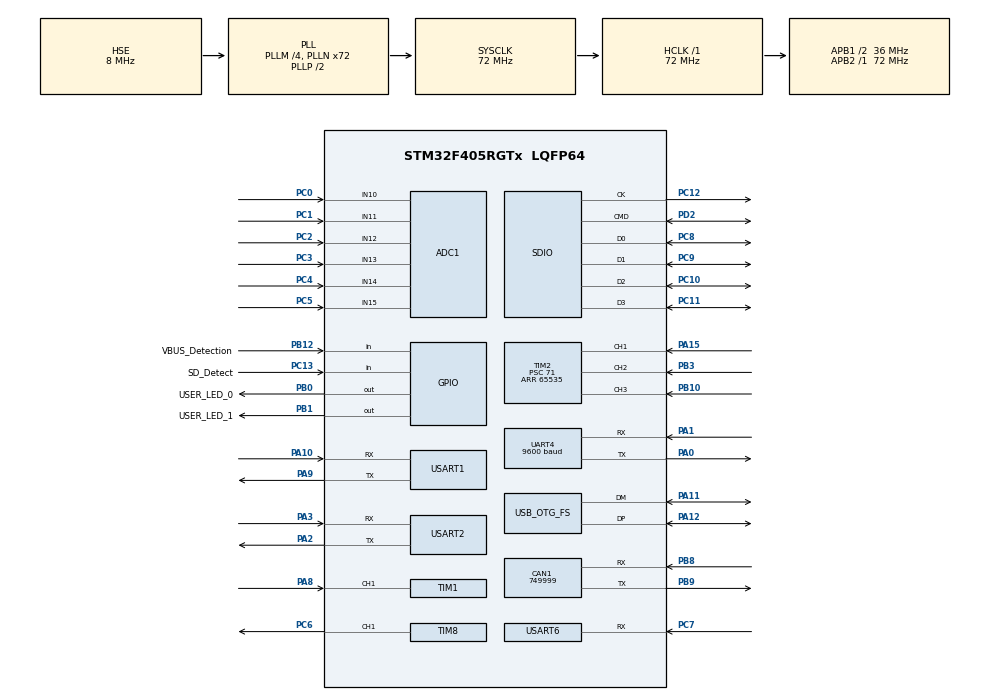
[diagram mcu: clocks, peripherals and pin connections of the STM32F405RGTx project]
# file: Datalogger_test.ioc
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ADC1.Channel-0\#ChannelRegularConversion=ADC_CHANNEL_10
ADC1.ExternalTrigConv=ADC_EXTERNALTRIGCONV_T3_TRGO
ADC1.NbrOfConversionFlag=1
ADC1.Rank-0\#ChannelRegularConversion=1
ADC1.SamplingTime-0\#ChannelRegularConversion=ADC_SAMPLETIME_3CYCLES
ADC1.ScanConvMode=ENABLE
ADC1.master=1
CAN1.CalculateBaudRate=749999
CAN1.CalculateTimeBit=1333
CAN1.CalculateTimeQuantum=444.44444444444446
Dma.ADC1.0.Direction=DMA_PERIPH_TO_MEMORY
Dma.ADC1.0.FIFOMode=DMA_FIFOMODE_DISABLE
Dma.ADC1.0.Instance=DMA2_Stream0
Dma.ADC1.0.MemDataAlignment=DMA_MDATAALIGN_HALFWORD
Dma.ADC1.0.MemInc=DMA_MINC_ENABLE
Dma.ADC1.0.Mode=DMA_CIRCULAR
Dma.ADC1.0.PeriphDataAlignment=DMA_PDATAALIGN_HALFWORD
Dma.ADC1.0.PeriphInc=DMA_PINC_DISABLE
Dma.ADC1.0.Priority=DMA_PRIORITY_HIGH
Dma.Request0=ADC1
Dma.Request1=TIM8_CH1
Dma.Request2=USART6_RX
Dma.TIM8_CH1.1.Direction=DMA_MEMORY_TO_PERIPH
Dma.TIM8_CH1.1.FIFOMode=DMA_FIFOMODE_DISABLE
Dma.TIM8_CH1.1.Instance=DMA2_Stream2
Dma.TIM8_CH1.1.MemDataAlignment=DMA_MDATAALIGN_HALFWORD
Dma.TIM8_CH1.1.MemInc=DMA_MINC_ENABLE
Dma.TIM8_CH1.1.Mode=DMA_NORMAL
Dma.TIM8_CH1.1.PeriphDataAlignment=DMA_PDATAALIGN_HALFWORD
Dma.TIM8_CH1.1.PeriphInc=DMA_PINC_DISABLE
Dma.TIM8_CH1.1.Priority=DMA_PRIORITY_LOW
Dma.USART6_RX.2.Direction=DMA_PERIPH_TO_MEMORY
Dma.USART6_RX.2.FIFOMode=DMA_FIFOMODE_DISABLE
Dma.USART6_RX.2.Instance=DMA2_Stream1
Dma.USART6_RX.2.MemDataAlignment=DMA_MDATAALIGN_BYTE
Dma.USART6_RX.2.MemInc=DMA_MINC_ENABLE
Dma.USART6_RX.2.Mode=DMA_CIRCULAR
Dma.USART6_RX.2.PeriphDataAlignment=DMA_PDATAALIGN_BYTE
Dma.USART6_RX.2.PeriphInc=DMA_PINC_DISABLE
Dma.USART6_RX.2.Priority=DMA_PRIORITY_HIGH
FATFS.BSP.number=1
FATFS._USE_LFN=1
FATFS0.BSP.STBoard=false
FATFS0.BSP.api=Unknown
FATFS0.BSP.instance=PC13-ANTI_TAMP
FATFS0.BSP.ip=GPIO
FATFS0.BSP.mode=Input
FATFS0.BSP.name=Detect_SDIO
FATFS0.BSP.solution=PC13-ANTI_TAMP
Mcu.Family=STM32F4
Mcu.Name=STM32F405RGTx
Mcu.Package=LQFP64
NVIC.DMA2_Stream0_IRQn=true\:0\:0\:false\:false\:true\:false\:true\:true
NVIC.DMA2_Stream1_IRQn=true\:5\:0\:false\:false\:true\:false\:true\:true
NVIC.DMA2_Stream2_IRQn=true\:0\:0\:false\:false\:true\:false\:true\:true
NVIC.OTG_FS_IRQn=true\:0\:0\:false\:false\:true\:false\:true\:true
NVIC.PriorityGroup=NVIC_PRIORITYGROUP_4
NVIC.TIM1_CC_IRQn=true\:0\:0\:false\:false\:true\:true\:true\:true
NVIC.USART1_IRQn=true\:0\:0\:false\:false\:true\:true\:true\:true
NVIC.USART2_IRQn=true\:0\:0\:false\:false\:true\:true\:true\:true
NVIC.USART6_IRQn=true\:5\:0\:false\:false\:true\:true\:true\:true
PA0-WKUP.Mode=Asynchronous
PA0-WKUP.Signal=UART4_TX
PA1.Mode=Asynchronous
PA1.Signal=UART4_RX
PA10.Mode=Asynchronous
PA10.Signal=USART1_RX
PA11.Mode=Device_Only
PA11.Signal=USB_OTG_FS_DM
PA12.Mode=Device_Only
PA12.Signal=USB_OTG_FS_DP
PA13.Mode=Serial_Wire
PA13.Signal=SYS_JTMS-SWDIO
PA14.Mode=Serial_Wire
PA14.Signal=SYS_JTCK-SWCLK
PA15.Signal=S_TIM2_CH1_ETR
PA2.Mode=Asynchronous
PA2.Signal=USART2_TX
PA3.Mode=Asynchronous
PA3.Signal=USART2_RX
PA8.Signal=S_TIM1_CH1
PA9.Mode=Asynchronous
PA9.Signal=USART1_TX
PC7.Mode=Asynchronous
PC7.Signal=USART6_RX
PB0.GPIO_Label=USER_LED_0
PB0.Signal=GPIO_Output
PB1.GPIO_Label=USER_LED_1
PB1.Signal=GPIO_Output
PB10.Signal=S_TIM2_CH3
PB12.GPIO_Label=VBUS_Detection
PB12.Signal=GPIO_Input
PB3.Signal=S_TIM2_CH2
PB8.Mode=CAN_Activate
PB8.Signal=CAN1_RX
PB9.Mode=CAN_Activate
PB9.Signal=CAN1_TX
PC0.Signal=ADCx_IN10
PC1.Signal=ADCx_IN11
PC10.Mode=SD_4_bits_Wide_bus
PC10.Signal=SDIO_D2
PC11.Mode=SD_4_bits_Wide_bus
PC11.Signal=SDIO_D3
PC12.Mode=SD_4_bits_Wide_bus
PC12.Signal=SDIO_CK
PC13-ANTI_TAMP.GPIO_Label=SD_Detect
PC13-ANTI_TAMP.Signal=GPIO_Input
PC2.Signal=ADCx_IN12
PC3.Signal=ADCx_IN13
PC4.Signal=ADCx_IN14
PC5.Signal=ADCx_IN15
PC6.Signal=S_TIM8_CH1
PC8.Mode=SD_4_bits_Wide_bus
PC8.Signal=SDIO_D0
PC9.Mode=SD_4_bits_Wide_bus
PC9.Signal=SDIO_D1
PD2.Mode=SD_4_bits_Wide_bus
PD2.Signal=SDIO_CMD
PH0-OSC_IN.Mode=HSE-External-Oscillator
PH0-OSC_IN.Signal=RCC_OSC_IN
PH1-OSC_OUT.Mode=HSE-External-Oscillator
PH1-OSC_OUT.Signal=RCC_OSC_OUT
ProjectManager.HeapSize=0x400
ProjectManager.StackSize=0x800
ProjectManager.TargetToolchain=STM32CubeIDE
RCC.48MHZClocksFreq_Value=48000000
RCC.AHBFreq_Value=72000000
RCC.APB1CLKDivider=RCC_HCLK_DIV2
RCC.APB1Freq_Value=36000000
RCC.APB1TimFreq_Value=72000000
RCC.APB2Freq_Value=72000000
RCC.APB2TimFreq_Value=72000000
RCC.CortexFreq_Value=72000000
RCC.HCLKFreq_Value=72000000
RCC.HSE_VALUE=8000000
RCC.HSI_VALUE=16000000
RCC.LSE_VALUE=32768
RCC.PLLM=4
RCC.PLLN=72
RCC.PLLQ=3
RCC.SYSCLKFreq_VALUE=72000000
RCC.SYSCLKSource=RCC_SYSCLKSOURCE_PLLCLK
RCC.VCOOutputFreq_Value=144000000
SDIO.ClockDiv=4
SH.ADCx_IN10.0=ADC1_IN10,IN10
SH.ADCx_IN11.0=ADC1_IN11,IN11
SH.ADCx_IN12.0=ADC1_IN12,IN12
SH.ADCx_IN13.0=ADC1_IN13,IN13
SH.ADCx_IN14.0=ADC1_IN14,IN14
SH.ADCx_IN15.0=ADC1_IN15,IN15
SH.S_TIM1_CH1.0=TIM1_CH1,Input_Capture1_from_TI1
SH.S_TIM2_CH1_ETR.0=TIM2_CH1,Input_Capture1_from_TI1
SH.S_TIM2_CH2.0=TIM2_CH2,Input_Capture2_from_TI2
SH.S_TIM2_CH3.0=TIM2_CH3,Input_Capture3_from_TI3
SH.S_TIM8_CH1.0=TIM8_CH1,PWM Generation1 CH1
TIM1.Channel-Input_Capture1_from_TI1=TIM_CHANNEL_1
TIM1.ICPolarity_CH1=TIM_INPUTCHANNELPOLARITY_FALLING
TIM1.Prescaler=71
TIM2.Channel-Input_Capture1_from_TI1=TIM_CHANNEL_1
TIM2.Channel-Input_Capture2_from_TI2=TIM_CHANNEL_2
TIM2.Channel-Input_Capture3_from_TI3=TIM_CHANNEL_3
TIM2.ICPolarity_CH1=TIM_INPUTCHANNELPOLARITY_FALLING
TIM2.ICPolarity_CH2=TIM_INPUTCHANNELPOLARITY_FALLING
TIM2.ICPolarity_CH3=TIM_INPUTCHANNELPOLARITY_FALLING
TIM2.Period=65535
TIM2.Prescaler=71
TIM3.MasterOutputTrigger=TIM_TRGO_UPDATE
TIM3.Period=9999
TIM3.Prescaler=71
TIM8.Channel-PWM\ Generation1\ CH1=TIM_CHANNEL_1
TIM8.Period=89
UART4.BaudRate=9600
UART4.VirtualMode=Asynchronous
USART1.VirtualMode=VM_ASYNC
USART2.VirtualMode=VM_ASYNC
USART6.BaudRate=115200
USART6.Mode=MODE_RX
USART6.VirtualMode=VM_ASYNC
USB_DEVICE.CLASS_NAME_FS=MSC
USB_DEVICE.VirtualMode-MSC_FS=Msc
USB_DEVICE.VirtualModeFS=Msc_FS
USB_OTG_FS.VirtualMode=Device_Only
VP_FATFS_VS_SDIO.Mode=SDIO
VP_TIM2_VS_ClockSourceINT.Mode=Internal
VP_USB_DEVICE_VS_USB_DEVICE_MSC_FS.Mode=MSC_FS
board=custom

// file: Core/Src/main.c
/* USER CODE BEGIN Header */
/**
 ******************************************************************************
 * @file           : main.c
 * @brief          : Main program body
 ******************************************************************************
 * @attention
 *
 * Copyright (c) 2026 STMicroelectronics.
 * All rights reserved.
 *
 * This software is licensed under terms that can be found in the LICENSE file
 * in the root directory of this software component.
 * If no LICENSE file comes with this software, it is provided AS-IS.
 *
 ******************************************************************************
 */
/* USER CODE END Header */
#include "main.h"
#include "fatfs.h"
#include "usb_device.h"

/* USER CODE BEGIN Includes */
#include "app_internal.h"
/* USER CODE END Includes */

ADC_HandleTypeDef hadc1;
DMA_HandleTypeDef hdma_adc1;

CAN_HandleTypeDef hcan1;

SD_HandleTypeDef hsd;

TIM_HandleTypeDef htim1;
TIM_HandleTypeDef htim2;
TIM_HandleTypeDef htim3;
TIM_HandleTypeDef htim8;
DMA_HandleTypeDef hdma_tim8_ch1;

UART_HandleTypeDef huart4;
UART_HandleTypeDef huart1;
UART_HandleTypeDef huart2;
UART_HandleTypeDef huart6;
DMA_HandleTypeDef hdma_usart6_rx;

void SystemClock_Config(void);
static void MX_GPIO_Init(void);
static void MX_DMA_Init(void);
static void MX_SDIO_SD_Init(void);
static void MX_CAN1_Init(void);
static void MX_TIM1_Init(void);
static void MX_ADC1_Init(void);
static void MX_TIM2_Init(void);
static void MX_TIM3_Init(void);
static void MX_UART4_Init(void);
static void MX_USART1_UART_Init(void);
static void MX_USART2_UART_Init(void);
static void MX_USART6_UART_Init(void);
static void MX_TIM8_Init(void);

int main(void) {

  /* MCU Configuration--------------------------------------------------------*/

  /* Reset of all peripherals, Initializes the Flash interface and the Systick.
   */
  HAL_Init();

  /* Configure the system clock */
  SystemClock_Config();

  /* Initialize all configured peripherals */
  MX_GPIO_Init();
  MX_DMA_Init();
  MX_SDIO_SD_Init();
  MX_FATFS_Init();
  MX_CAN1_Init();
  MX_TIM1_Init();
  MX_TIM2_Init();
  MX_TIM3_Init();
  MX_ADC1_Init();
  MX_UART4_Init();
  MX_USART1_UART_Init();
  MX_USART2_UART_Init();
  MX_USART6_UART_Init();
  MX_TIM8_Init();

  /* USER CODE BEGIN 2 */
App_Init();
/* USER CODE END 2 */

  /* Infinite loop */
  while (1) {

    /* USER CODE BEGIN 3 */
    App_Process();
  }
  /* USER CODE END 3 */
}

void SystemClock_Config(void) {
  RCC_OscInitTypeDef RCC_OscInitStruct = {0};
  RCC_ClkInitTypeDef RCC_ClkInitStruct = {0};

  /** Configure the main internal regulator output voltage
   */
  __HAL_RCC_PWR_CLK_ENABLE();
  __HAL_PWR_VOLTAGESCALING_CONFIG(PWR_REGULATOR_VOLTAGE_SCALE1);

  /** Initializes the RCC Oscillators according to the specified parameters
   * in the RCC_OscInitTypeDef structure.
   */
  RCC_OscInitStruct.OscillatorType = RCC_OSCILLATORTYPE_HSE;
  RCC_OscInitStruct.HSEState = RCC_HSE_ON;
  RCC_OscInitStruct.PLL.PLLState = RCC_PLL_ON;
  RCC_OscInitStruct.PLL.PLLSource = RCC_PLLSOURCE_HSE;
  RCC_OscInitStruct.PLL.PLLM = 4;
  RCC_OscInitStruct.PLL.PLLN = 72;
  RCC_OscInitStruct.PLL.PLLP = RCC_PLLP_DIV2;
  RCC_OscInitStruct.PLL.PLLQ = 3;
  if (HAL_RCC_OscConfig(&RCC_OscInitStruct) != HAL_OK) {
    Error_Handler();
  }

  /** Initializes the CPU, AHB and APB buses clocks
   */
  RCC_ClkInitStruct.ClockType = RCC_CLOCKTYPE_HCLK | RCC_CLOCKTYPE_SYSCLK |
                                RCC_CLOCKTYPE_PCLK1 | RCC_CLOCKTYPE_PCLK2;
  RCC_ClkInitStruct.SYSCLKSource = RCC_SYSCLKSOURCE_PLLCLK;
  RCC_ClkInitStruct.AHBCLKDivider = RCC_SYSCLK_DIV1;
  RCC_ClkInitStruct.APB1CLKDivider = RCC_HCLK_DIV2;
  RCC_ClkInitStruct.APB2CLKDivider = RCC_HCLK_DIV1;

  if (HAL_RCC_ClockConfig(&RCC_ClkInitStruct, FLASH_LATENCY_2) != HAL_OK) {
    Error_Handler();
  }
}

static void MX_ADC1_Init(void) {
  static const uint32_t adc_channels[ADC_DMA_CHANNEL_COUNT] = {
      ADC_CHANNEL_10, ADC_CHANNEL_13, ADC_CHANNEL_14, ADC_CHANNEL_15};
  ADC_ChannelConfTypeDef sConfig = {0};

  hadc1.Instance = ADC1;
  hadc1.Init.ClockPrescaler = ADC_CLOCK_SYNC_PCLK_DIV2;
  hadc1.Init.Resolution = ADC_RESOLUTION_12B;
  hadc1.Init.ScanConvMode = ENABLE;
  hadc1.Init.ContinuousConvMode = DISABLE;
  hadc1.Init.DiscontinuousConvMode = DISABLE;
  hadc1.Init.ExternalTrigConvEdge = ADC_EXTERNALTRIGCONVEDGE_RISING;
  hadc1.Init.ExternalTrigConv = ADC_EXTERNALTRIGCONV_T3_TRGO;
  hadc1.Init.DataAlign = ADC_DATAALIGN_RIGHT;
  hadc1.Init.NbrOfConversion = ADC_DMA_CHANNEL_COUNT;
  hadc1.Init.DMAContinuousRequests = ENABLE;
  hadc1.Init.EOCSelection = ADC_EOC_SEQ_CONV;
  if (HAL_ADC_Init(&hadc1) != HAL_OK) {
    Error_Handler();
  }

  sConfig.SamplingTime = ADC_SAMPLETIME_480CYCLES;
  for (uint32_t i = 0U; i < ADC_DMA_CHANNEL_COUNT; i++) {
    sConfig.Channel = adc_channels[i];
    sConfig.Rank = (uint32_t)(i + 1U);
    if (HAL_ADC_ConfigChannel(&hadc1, &sConfig) != HAL_OK) {
      Error_Handler();
    }
  }
}

static void MX_CAN1_Init(void) {

  hcan1.Instance = CAN1;
  hcan1.Init.Prescaler = 16;
  hcan1.Init.Mode = CAN_MODE_NORMAL;
  hcan1.Init.SyncJumpWidth = CAN_SJW_1TQ;
  hcan1.Init.TimeSeg1 = CAN_BS1_1TQ;
  hcan1.Init.TimeSeg2 = CAN_BS2_1TQ;
  hcan1.Init.TimeTriggeredMode = DISABLE;
  hcan1.Init.AutoBusOff = DISABLE;
  hcan1.Init.AutoWakeUp = DISABLE;
  hcan1.Init.AutoRetransmission = DISABLE;
  hcan1.Init.ReceiveFifoLocked = DISABLE;
  hcan1.Init.TransmitFifoPriority = DISABLE;
  if (HAL_CAN_Init(&hcan1) != HAL_OK) {
    Error_Handler();
  }
}

static void MX_SDIO_SD_Init(void) {

  hsd.Instance = SDIO;
  hsd.Init.ClockEdge = SDIO_CLOCK_EDGE_RISING;
  hsd.Init.ClockBypass = SDIO_CLOCK_BYPASS_DISABLE;
  hsd.Init.ClockPowerSave = SDIO_CLOCK_POWER_SAVE_DISABLE;
  hsd.Init.BusWide = SDIO_BUS_WIDE_1B;
  hsd.Init.HardwareFlowControl = SDIO_HARDWARE_FLOW_CONTROL_DISABLE;
  hsd.Init.ClockDiv = 4;
  /* USER CODE BEGIN SDIO_Init 2 */
  /* The logger writes slowly, so prefer signal margin over bus speed. Hardware
   * flow control also lets SDIO pause the clock while the FIFO is tight, which
   * is useful with long wires or marginal cards.
   */
  hsd.Init.HardwareFlowControl = SDIO_HARDWARE_FLOW_CONTROL_ENABLE;
  hsd.Init.ClockDiv = 12;

  /* USER CODE END SDIO_Init 2 */
}

static void MX_TIM1_Init(void) {

  TIM_MasterConfigTypeDef sMasterConfig = {0};
  TIM_IC_InitTypeDef sConfigIC = {0};

  htim1.Instance = TIM1;
  htim1.Init.Prescaler = 71;
  htim1.Init.CounterMode = TIM_COUNTERMODE_UP;
  htim1.Init.Period = 65535;
  htim1.Init.ClockDivision = TIM_CLOCKDIVISION_DIV1;
  htim1.Init.RepetitionCounter = 0;
  htim1.Init.AutoReloadPreload = TIM_AUTORELOAD_PRELOAD_DISABLE;
  if (HAL_TIM_IC_Init(&htim1) != HAL_OK) {
    Error_Handler();
  }
  sMasterConfig.MasterOutputTrigger = TIM_TRGO_RESET;
  sMasterConfig.MasterSlaveMode = TIM_MASTERSLAVEMODE_DISABLE;
  if (HAL_TIMEx_MasterConfigSynchronization(&htim1, &sMasterConfig) != HAL_OK) {
    Error_Handler();
  }
  sConfigIC.ICPolarity = TIM_INPUTCHANNELPOLARITY_FALLING;
  sConfigIC.ICSelection = TIM_ICSELECTION_DIRECTTI;
  sConfigIC.ICPrescaler = TIM_ICPSC_DIV1;
  sConfigIC.ICFilter = 0;
  if (HAL_TIM_IC_ConfigChannel(&htim1, &sConfigIC, TIM_CHANNEL_1) != HAL_OK) {
    Error_Handler();
  }
}

static void MX_TIM2_Init(void) {

  TIM_ClockConfigTypeDef sClockSourceConfig = {0};
  TIM_MasterConfigTypeDef sMasterConfig = {0};
  TIM_IC_InitTypeDef sConfigIC = {0};

  htim2.Instance = TIM2;
  htim2.Init.Prescaler = 71;
  htim2.Init.CounterMode = TIM_COUNTERMODE_UP;
  htim2.Init.Period = 65535;
  htim2.Init.ClockDivision = TIM_CLOCKDIVISION_DIV1;
  htim2.Init.AutoReloadPreload = TIM_AUTORELOAD_PRELOAD_DISABLE;
  if (HAL_TIM_Base_Init(&htim2) != HAL_OK) {
    Error_Handler();
  }
  sClockSourceConfig.ClockSource = TIM_CLOCKSOURCE_INTERNAL;
  if (HAL_TIM_ConfigClockSource(&htim2, &sClockSourceConfig) != HAL_OK) {
    Error_Handler();
  }
  if (HAL_TIM_IC_Init(&htim2) != HAL_OK) {
    Error_Handler();
  }
  sMasterConfig.MasterOutputTrigger = TIM_TRGO_RESET;
  sMasterConfig.MasterSlaveMode = TIM_MASTERSLAVEMODE_DISABLE;
  if (HAL_TIMEx_MasterConfigSynchronization(&htim2, &sMasterConfig) != HAL_OK) {
    Error_Handler();
  }
  sConfigIC.ICPolarity = TIM_INPUTCHANNELPOLARITY_FALLING;
  sConfigIC.ICSelection = TIM_ICSELECTION_DIRECTTI;
  sConfigIC.ICPrescaler = TIM_ICPSC_DIV1;
  sConfigIC.ICFilter = 0;
  if (HAL_TIM_IC_ConfigChannel(&htim2, &sConfigIC, TIM_CHANNEL_1) != HAL_OK) {
    Error_Handler();
  }
  if (HAL_TIM_IC_ConfigChannel(&htim2, &sConfigIC, TIM_CHANNEL_2) != HAL_OK) {
    Error_Handler();
  }
  if (HAL_TIM_IC_ConfigChannel(&htim2, &sConfigIC, TIM_CHANNEL_3) != HAL_OK) {
    Error_Handler();
  }
}

static void MX_TIM3_Init(void) {
  TIM_ClockConfigTypeDef sClockSourceConfig = {0};
  TIM_MasterConfigTypeDef sMasterConfig = {0};

  /* 72 MHz APB1 timer clock / 72 = 1 MHz. An update every 10,000 ticks
   * provides a dedicated 100 Hz trigger for the four local ADC channels. */
  htim3.Instance = TIM3;
  htim3.Init.Prescaler = 71;
  htim3.Init.CounterMode = TIM_COUNTERMODE_UP;
  htim3.Init.Period = 9999;
  htim3.Init.ClockDivision = TIM_CLOCKDIVISION_DIV1;
  htim3.Init.AutoReloadPreload = TIM_AUTORELOAD_PRELOAD_DISABLE;
  if (HAL_TIM_Base_Init(&htim3) != HAL_OK) {
    Error_Handler();
  }

  sClockSourceConfig.ClockSource = TIM_CLOCKSOURCE_INTERNAL;
  if (HAL_TIM_ConfigClockSource(&htim3, &sClockSourceConfig) != HAL_OK) {
    Error_Handler();
  }

  sMasterConfig.MasterOutputTrigger = TIM_TRGO_UPDATE;
  sMasterConfig.MasterSlaveMode = TIM_MASTERSLAVEMODE_DISABLE;
  if (HAL_TIMEx_MasterConfigSynchronization(&htim3, &sMasterConfig) != HAL_OK) {
    Error_Handler();
  }
}

static void MX_TIM8_Init(void) {

  TIM_MasterConfigTypeDef sMasterConfig = {0};
  TIM_OC_InitTypeDef sConfigOC = {0};
  TIM_BreakDeadTimeConfigTypeDef sBreakDeadTimeConfig = {0};

  htim8.Instance = TIM8;
  htim8.Init.Prescaler = 0;
  htim8.Init.CounterMode = TIM_COUNTERMODE_UP;
  htim8.Init.Period = 89;
  htim8.Init.ClockDivision = TIM_CLOCKDIVISION_DIV1;
  htim8.Init.RepetitionCounter = 0;
  htim8.Init.AutoReloadPreload = TIM_AUTORELOAD_PRELOAD_DISABLE;
  if (HAL_TIM_PWM_Init(&htim8) != HAL_OK) {
    Error_Handler();
  }
  sMasterConfig.MasterOutputTrigger = TIM_TRGO_RESET;
  sMasterConfig.MasterSlaveMode = TIM_MASTERSLAVEMODE_DISABLE;
  if (HAL_TIMEx_MasterConfigSynchronization(&htim8, &sMasterConfig) != HAL_OK) {
    Error_Handler();
  }
  sConfigOC.OCMode = TIM_OCMODE_PWM1;
  sConfigOC.Pulse = 0;
  sConfigOC.OCPolarity = TIM_OCPOLARITY_HIGH;
  sConfigOC.OCNPolarity = TIM_OCNPOLARITY_HIGH;
  sConfigOC.OCFastMode = TIM_OCFAST_DISABLE;
  sConfigOC.OCIdleState = TIM_OCIDLESTATE_RESET;
  sConfigOC.OCNIdleState = TIM_OCNIDLESTATE_RESET;
  if (HAL_TIM_PWM_ConfigChannel(&htim8, &sConfigOC, TIM_CHANNEL_1) != HAL_OK) {
    Error_Handler();
  }
  sBreakDeadTimeConfig.OffStateRunMode = TIM_OSSR_DISABLE;
  sBreakDeadTimeConfig.OffStateIDLEMode = TIM_OSSI_DISABLE;
  sBreakDeadTimeConfig.LockLevel = TIM_LOCKLEVEL_OFF;
  sBreakDeadTimeConfig.DeadTime = 0;
  sBreakDeadTimeConfig.BreakState = TIM_BREAK_DISABLE;
  sBreakDeadTimeConfig.BreakPolarity = TIM_BREAKPOLARITY_HIGH;
  sBreakDeadTimeConfig.AutomaticOutput = TIM_AUTOMATICOUTPUT_DISABLE;
  if (HAL_TIMEx_ConfigBreakDeadTime(&htim8, &sBreakDeadTimeConfig) != HAL_OK) {
    Error_Handler();
  }
  HAL_TIM_MspPostInit(&htim8);
}

static void MX_UART4_Init(void) {

  huart4.Instance = UART4;
  huart4.Init.BaudRate = 9600;
  huart4.Init.WordLength = UART_WORDLENGTH_8B;
  huart4.Init.StopBits = UART_STOPBITS_1;
  huart4.Init.Parity = UART_PARITY_NONE;
  huart4.Init.Mode = UART_MODE_TX_RX;
  huart4.Init.HwFlowCtl = UART_HWCONTROL_NONE;
  huart4.Init.OverSampling = UART_OVERSAMPLING_16;
  if (HAL_UART_Init(&huart4) != HAL_OK) {
    Error_Handler();
  }
}

static void MX_USART1_UART_Init(void) {

  huart1.Instance = USART1;
  huart1.Init.BaudRate = 115200;
  huart1.Init.WordLength = UART_WORDLENGTH_8B;
  huart1.Init.StopBits = UART_STOPBITS_1;
  huart1.Init.Parity = UART_PARITY_NONE;
  huart1.Init.Mode = UART_MODE_TX_RX;
  huart1.Init.HwFlowCtl = UART_HWCONTROL_NONE;
  huart1.Init.OverSampling = UART_OVERSAMPLING_16;
  if (HAL_UART_Init(&huart1) != HAL_OK) {
    Error_Handler();
  }
}

static void MX_USART2_UART_Init(void) {

  huart2.Instance = USART2;
  huart2.Init.BaudRate = 115200;
  huart2.Init.WordLength = UART_WORDLENGTH_8B;
  huart2.Init.StopBits = UART_STOPBITS_1;
  huart2.Init.Parity = UART_PARITY_NONE;
  huart2.Init.Mode = UART_MODE_TX_RX;
  huart2.Init.HwFlowCtl = UART_HWCONTROL_NONE;
  huart2.Init.OverSampling = UART_OVERSAMPLING_16;
  if (HAL_UART_Init(&huart2) != HAL_OK) {
    Error_Handler();
  }
}

static void MX_USART6_UART_Init(void) {
  huart6.Instance = USART6;
  huart6.Init.BaudRate = 115200;
  huart6.Init.WordLength = UART_WORDLENGTH_8B;
  huart6.Init.StopBits = UART_STOPBITS_1;
  huart6.Init.Parity = UART_PARITY_NONE;
  huart6.Init.Mode = UART_MODE_RX;
  huart6.Init.HwFlowCtl = UART_HWCONTROL_NONE;
  huart6.Init.OverSampling = UART_OVERSAMPLING_16;
  if (HAL_UART_Init(&huart6) != HAL_OK) {
    Error_Handler();
  }
}

static void MX_DMA_Init(void) {

  /* DMA controller clock enable */
  __HAL_RCC_DMA2_CLK_ENABLE();

  /* DMA interrupt init */
  /* DMA2_Stream0_IRQn interrupt configuration */
  HAL_NVIC_SetPriority(DMA2_Stream0_IRQn, 0, 0);
  HAL_NVIC_EnableIRQ(DMA2_Stream0_IRQn);
  /* DMA2_Stream2_IRQn interrupt configuration */
  HAL_NVIC_SetPriority(DMA2_Stream2_IRQn, 0, 0);
  HAL_NVIC_EnableIRQ(DMA2_Stream2_IRQn);
  /* DMA2_Stream1_IRQn interrupt configuration (USART6 RX) */
  HAL_NVIC_SetPriority(DMA2_Stream1_IRQn, 5, 0);
  HAL_NVIC_EnableIRQ(DMA2_Stream1_IRQn);
}

static void MX_GPIO_Init(void) {
  GPIO_InitTypeDef GPIO_InitStruct = {0};

  /* GPIO Ports Clock Enable */
  __HAL_RCC_GPIOC_CLK_ENABLE();
  __HAL_RCC_GPIOH_CLK_ENABLE();
  __HAL_RCC_GPIOA_CLK_ENABLE();
  __HAL_RCC_GPIOB_CLK_ENABLE();
  __HAL_RCC_GPIOD_CLK_ENABLE();

  /*Configure GPIO pin Output Level */
  HAL_GPIO_WritePin(GPIOB, USER_LED_0_Pin | USER_LED_1_Pin, GPIO_PIN_RESET);

  /*Configure GPIO pin : SD_Detect_Pin */
  GPIO_InitStruct.Pin = SD_Detect_Pin;
  GPIO_InitStruct.Mode = GPIO_MODE_INPUT;
  GPIO_InitStruct.Pull = GPIO_NOPULL;
  HAL_GPIO_Init(SD_Detect_GPIO_Port, &GPIO_InitStruct);

  /*Configure GPIO pins : USER_LED_0_Pin USER_LED_1_Pin */
  GPIO_InitStruct.Pin = USER_LED_0_Pin | USER_LED_1_Pin;
  GPIO_InitStruct.Mode = GPIO_MODE_OUTPUT_PP;
  GPIO_InitStruct.Pull = GPIO_NOPULL;
  GPIO_InitStruct.Speed = GPIO_SPEED_FREQ_LOW;
  HAL_GPIO_Init(GPIOB, &GPIO_InitStruct);

  /*Configure GPIO pin : VBUS_Detection_Pin */
  GPIO_InitStruct.Pin = VBUS_Detection_Pin;
  GPIO_InitStruct.Mode = GPIO_MODE_INPUT;
  GPIO_InitStruct.Pull = GPIO_NOPULL;
  HAL_GPIO_Init(VBUS_Detection_GPIO_Port, &GPIO_InitStruct);

}

void Error_Handler(void) {
  /* USER CODE BEGIN Error_Handler_Debug */
  /* User can add his own implementation to report the HAL error return state */
  LED_Set(USER_LED_0_GPIO_Port, USER_LED_0_Pin, GPIO_PIN_RESET);
  while (1) {
    HAL_GPIO_TogglePin(USER_LED_1_GPIO_Port, USER_LED_1_Pin);
    HAL_Delay(LED_BLINK_ON_MS);
  }
  /* USER CODE END Error_Handler_Debug */
}
#ifdef USE_FULL_ASSERT
/**
 * @brief  Reports the name of the source file and the source line number
 *         where the assert_param error has occurred.
 * @param  file: pointer to the source file name
 * @param  line: assert_param error line source number
 * @retval None
 */
void assert_failed(uint8_t *file, uint32_t line) {
  /* USER CODE BEGIN 6 */
  /* User can add his own implementation to report the file name and line
     number, ex: printf("Wrong parameters value: file %s on line %d\r\n", file,
     line) */
  /* USER CODE END 6 */
}
#endif /* USE_FULL_ASSERT */
